# R7FA6M4AF register map
Vendor: Renesas Electronics Corporation; Series: RA6; File version: 1.20.04
CPU: CM33 r0p4, little endian, MPU, FPU, VTOR, 4 interrupt priority bits, 96 interrupts
Registers are 8-bit, read-write, reset 0x0 unless marked. A register's access mark holds for its fields unless they carry their own. Offsets are from the block's base; [hi:lo] are bit positions; {n}, {i} and the like mark numbered series.

## CPSCU — CPU System Security Control Unit
Base 0x40008000
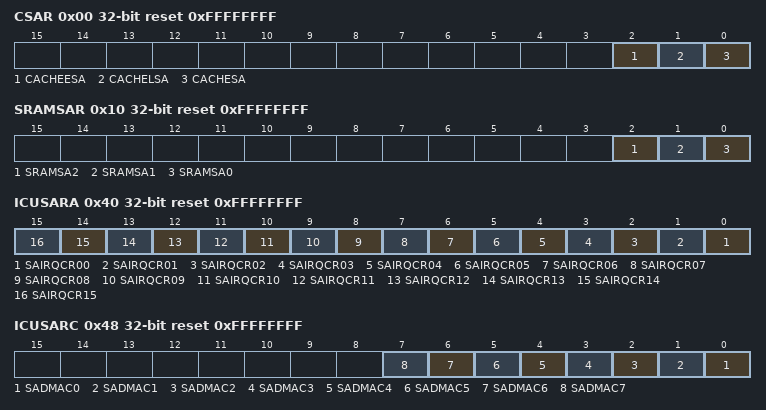
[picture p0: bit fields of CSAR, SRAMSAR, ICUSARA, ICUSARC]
0x00 CSAR 32-bit reset 0xFFFFFFFF — Cache Security Attribution Register
  [all] fields
    0=Secure; 1=Non-secure
  [2] CACHEESA — Security Attributes of Registers for Cache Error
  [1] CACHELSA — Security Attributes of Registers for Cache Line Configuration
  [0] CACHESA — Security Attributes of Registers for Cache Control
0x10 SRAMSAR 32-bit reset 0xFFFFFFFF — SRAM Security Attribution Register
  [all] fields
    0=Secure; 1=Non-Secure
  [2] SRAMSA2 — Security attributes of registers for ECC Relation
  [1] SRAMSA1 — Security attributes of registers for SRAM Protection 2
  [0] SRAMSA0 — Security attributes of registers for SRAM Protection
0x14 STBRAMSAR 32-bit reset 0xFFFFFFF0 — Standby RAM memory Security Attribution Register
  [3:0] NSBSTBR — Security attributes of each region for Standby RAM
    0=Region7-0 are all Secure; 1=Region7 is Non-secure. Region6-0 are Secure; 2=Region7-6 are Non-secure. Region5-0 are Secure.; 3=Region7-5 are Non-secure. Region4-0 are Secure.; 4=Region7-4 are Non-secure. Region 3-0 are Secure.; 5=Region7-3 are Non-secure. Region 2-0 are Secure.; 6=Region7-2 are Non-secure. Region 1-0 are Secure.; 7=Region7-1 are Non-Secure. Region0 is Secure.; other=Others (Region7-0 are all Non-Secure.)
0x30 DTCSAR 32-bit reset 0xFFFFFFFF — DTC Controller Security Attribution Register
  [0] DTCSTSA — DTC Security Attribution
    0=Secure; 1=Non-Secure
0x34 DMACSAR 32-bit reset 0xFFFFFFFF — DMAC Controller Security Attribution Register
  [0] DMASTSA — DMAST Security Attribution
    0=Secure; 1=Non-secure
0x40 ICUSARA 32-bit reset 0xFFFFFFFF — Interrupt Controller Unit Security Attribution Register A
  [all] fields
    0=Secure; 1=Non-secure
  [n] SAIRQCR{n:02} (n=0..15) — Security attributes of registers for the IRQCRn register
0x44 ICUSARB 32-bit reset 0xFFFFFFFF — Interrupt Controller Unit Security Attribution Register B
  [0] SANMI — Security attributes of registers for nonmaskable interrupt
    0=Secure; 1=Non-secure
0x48 ICUSARC 32-bit reset 0xFFFFFFFF — Interrupt Controller Unit Security Attribution Register C
  [all] fields
    0=Secure; 1=Non-secure
  [n] SADMAC{n} (n=0..7) — Security attributes of registers for DMAC channel
0x4C ICUSARD 32-bit reset 0xFFFFFFFF — Interrupt Controller Unit Security Attribution Register D
  [0] SASELSR0 — Security attributes of registers for SELSR0
    0=Secure; 1=Non-secure
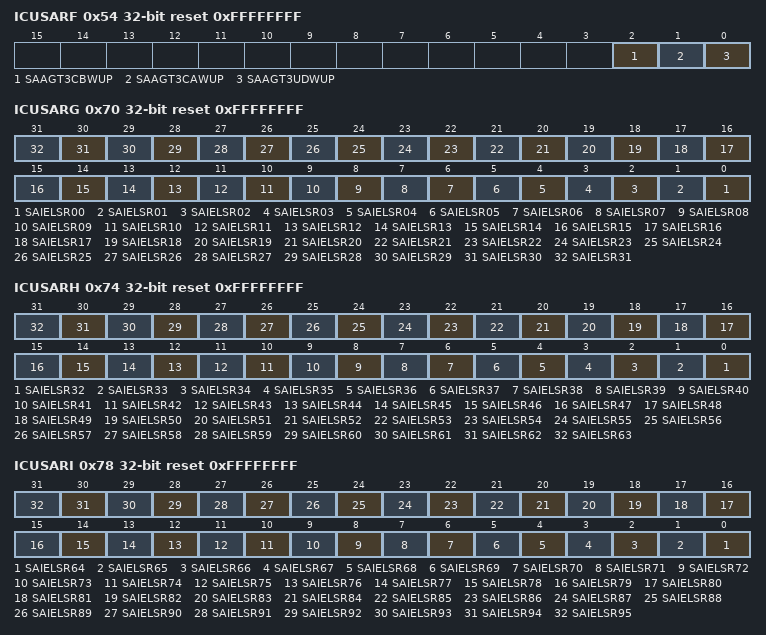
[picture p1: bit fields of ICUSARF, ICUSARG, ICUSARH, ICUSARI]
0x54 ICUSARF 32-bit reset 0xFFFFFFFF — Interrupt Controller Unit Security Attribution Register F
  [all] fields
    0=Secure; 1=Non-secure
  [2] SAAGT3CBWUP — Security attributes of registers for WUPEN1.b2
  [1] SAAGT3CAWUP — Security attributes of registers for WUPEN1.b1
  [0] SAAGT3UDWUP — Security attributes of registers for WUPEN1.b0
0x70 ICUSARG 32-bit reset 0xFFFFFFFF — Interrupt Controller Unit Security Attribution Register G
  [all] fields
    0=Secure; 1=Non-secure
  [n] SAIELSR{n:02} (n=0..31) — Security attributes of registers for IELSR31 to IELSR0
0x74 ICUSARH 32-bit reset 0xFFFFFFFF — Interrupt Controller Unit Security Attribution Register H
  [all] fields
    0=Secure; 1=Non-secure
  [n-32] SAIELSR{n} (n=32..63) — Security attributes of registers for IELSR63 to IELSR32
0x78 ICUSARI 32-bit reset 0xFFFFFFFF — Interrupt Controller Unit Security Attribution Register I
  [all] fields
    0=Secure; 1=Non-secure
  [n-64] SAIELSR{n} (n=64..95) — Security attributes of registers for IELSR95 to IELSR64
0x100 BUSSARA 32-bit reset 0xFFFFFFFF — BUS Security Attribution Register A
  [0] BUSSA0 — BUS Security Attribution A0
    0=Secure; 1=Non-Secure
0x104 BUSSARB 32-bit reset 0xFFFFFFFF — BUS Security Attribution Register B
  [0] BUSSB0 — BUS Security Attribution B0
    0=Secure; 1=Non-Secure
0x130 MMPUSARA 32-bit reset 0xFFFFFFFF — Master Memory Protection Unit Security Attribution Register A
  [7:0] MMPUASAn — MMPUA Security Attribution (n = 0 to 7)
    0=Secure; 1=Non-Secure
0x134 MMPUSARB 32-bit reset 0xFFFFFFFF — Master Memory Protection Unit Security Attribution Register B
  [0] MMPUBSA0 — MMPUB Security Attribution
    0=Secure; 1=Non-Secure
0x180 TZFSAR 32-bit reset 0xFFFFFFFE — TrustZone Filter Security Attribution Register
  [0] TZFSA0 — Security attributes of registers for TrustZone Filter
    0=Secure; 1=Non-secure
0x1B0 CPUDSAR 32-bit reset 0xFFFFFFFE — CPU Debug Security Attribution Register
  [0] CPUDSA0 — CPU Debug Security Attribution 0
    0=Secure; 1=Non-secure
